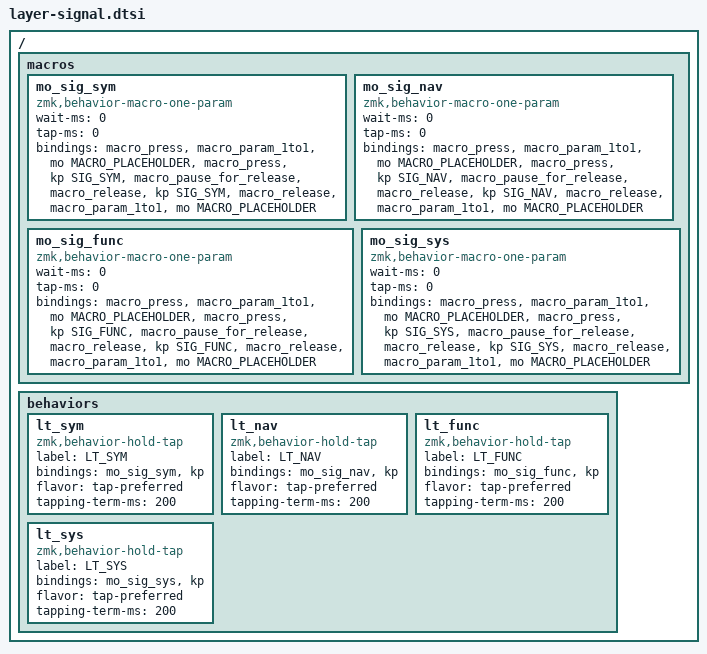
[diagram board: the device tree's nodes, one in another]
/*
 * レイヤー連動用の合図キー
 * ---------------------------------------------------------------------------
 * レイヤーに入るときに F13〜F16 を「押しっぱなし」にして PC に知らせる。
 * PC 側は RegisterHotKey でこれを受け取り、押している間だけオーバーレイを出す。
 * 予約したキーは他アプリに届かなくなるので、F13〜が漏れることはない（実測済み）。
 *
 * 使い方
 *   1. このファイルを zmk-config の config/ に置く
 *   2. Pyuron.keymap の #define L_BASE ... の直後で include する
 *        #include "layer-signal.dtsi"
 *   3. default_layer の親指キーを置き換える（引数はそのまま）
 *        &lt L_SYM  INT5   ->  &lt_sym  L_SYM  INT5
 *        &lt L_NAV  SPACE  ->  &lt_nav  L_NAV  SPACE
 *        &lt L_FUNC ENTER  ->  &lt_func L_FUNC ENTER
 *        &lt L_SYS  INT4   ->  &lt_sys  L_SYS  INT4
 *
 * L_MOUSE には合図キーを付けられない。トラックボール操作で
 * zip_mouse_temp_layer が自動 ON にするもので、キー押下を経由しないため
 * マクロを差し込む場所が無い。
 *
 * 設計上の制約
 *   ZMK の hold-tap は param1 を hold 側、param2 を tap 側へ固定で渡す。
 *   したがって #binding-cells は必ず <2> で、hold 側のビヘイビアは
 *   引数をちょうど 1 つ取る必要がある。そのため合図キーはマクロ側に焼き込み、
 *   レイヤー番号だけを引数で渡す形にしてある。
 *   合図キー 1 つにつきマクロ 1 つ、レイヤー 1 つにつき hold-tap 1 つ。
 */

#define SIG_SYM  F13
#define SIG_NAV  F14
#define SIG_FUNC F15
#define SIG_SYS  F16

/ {
    macros {
        /*
         * 引数で渡されたレイヤーに入りつつ、合図キーを押しっぱなしにする。
         *
         * wait-ms / tap-ms を 0 にしてあるのは必須。既定のままだと
         * バインディングの間に 100ms 入り、レイヤーが有効になるのが遅れて、
         * レイヤーに入った直後の打鍵が下のレイヤーに落ちる。
         * &mo を合図キーより先に置いているのも同じ理由。
         *
         * &macro_param_1to1 は「次のバインディングの第 1 引数に
         * マクロの第 1 引数を渡す」もので、次の 1 つにしか効かない。
         * 解放側でもう一度書いているのはそのため。
         */
        mo_sig_sym: mo_sig_sym {
            compatible = "zmk,behavior-macro-one-param";
            #binding-cells = <1>;
            wait-ms = <0>;
            tap-ms = <0>;
            bindings
                = <&macro_press &macro_param_1to1 &mo MACRO_PLACEHOLDER>
                , <&macro_press &kp SIG_SYM>
                , <&macro_pause_for_release>
                , <&macro_release &kp SIG_SYM>
                , <&macro_release &macro_param_1to1 &mo MACRO_PLACEHOLDER>;
        };

        mo_sig_nav: mo_sig_nav {
            compatible = "zmk,behavior-macro-one-param";
            #binding-cells = <1>;
            wait-ms = <0>;
            tap-ms = <0>;
            bindings
                = <&macro_press &macro_param_1to1 &mo MACRO_PLACEHOLDER>
                , <&macro_press &kp SIG_NAV>
                , <&macro_pause_for_release>
                , <&macro_release &kp SIG_NAV>
                , <&macro_release &macro_param_1to1 &mo MACRO_PLACEHOLDER>;
        };

        mo_sig_func: mo_sig_func {
            compatible = "zmk,behavior-macro-one-param";
            #binding-cells = <1>;
            wait-ms = <0>;
            tap-ms = <0>;
            bindings
                = <&macro_press &macro_param_1to1 &mo MACRO_PLACEHOLDER>
                , <&macro_press &kp SIG_FUNC>
                , <&macro_pause_for_release>
                , <&macro_release &kp SIG_FUNC>
                , <&macro_release &macro_param_1to1 &mo MACRO_PLACEHOLDER>;
        };

        mo_sig_sys: mo_sig_sys {
            compatible = "zmk,behavior-macro-one-param";
            #binding-cells = <1>;
            wait-ms = <0>;
            tap-ms = <0>;
            bindings
                = <&macro_press &macro_param_1to1 &mo MACRO_PLACEHOLDER>
                , <&macro_press &kp SIG_SYS>
                , <&macro_pause_for_release>
                , <&macro_release &kp SIG_SYS>
                , <&macro_release &macro_param_1to1 &mo MACRO_PLACEHOLDER>;
        };
    };

    behaviors {
        /*
         * 素の &lt の置き換え。呼び出し方も引数の並びも &lt と同じ。
         *
         * flavor と tapping-term-ms は ZMK 組み込みの &lt と同じ値にしてある
         * （tap-preferred / 200ms。ZMK の app/dts/behaviors/layer_tap.dtsi）。
         * 打鍵感を変えないため、ここは触らないこと。
         * 最初の版は hold-preferred と書いていたが、組み込みとは違っていた（2026-09-16 に修正）。
         */
        lt_sym: lt_sym {
            compatible = "zmk,behavior-hold-tap";
            label = "LT_SYM";
            #binding-cells = <2>;
            bindings = <&mo_sig_sym>, <&kp>;
            flavor = "tap-preferred";
            tapping-term-ms = <200>;
        };

        lt_nav: lt_nav {
            compatible = "zmk,behavior-hold-tap";
            label = "LT_NAV";
            #binding-cells = <2>;
            bindings = <&mo_sig_nav>, <&kp>;
            flavor = "tap-preferred";
            tapping-term-ms = <200>;
        };

        lt_func: lt_func {
            compatible = "zmk,behavior-hold-tap";
            label = "LT_FUNC";
            #binding-cells = <2>;
            bindings = <&mo_sig_func>, <&kp>;
            flavor = "tap-preferred";
            tapping-term-ms = <200>;
        };

        lt_sys: lt_sys {
            compatible = "zmk,behavior-hold-tap";
            label = "LT_SYS";
            #binding-cells = <2>;
            bindings = <&mo_sig_sys>, <&kp>;
            flavor = "tap-preferred";
            tapping-term-ms = <200>;
        };
    };
};
